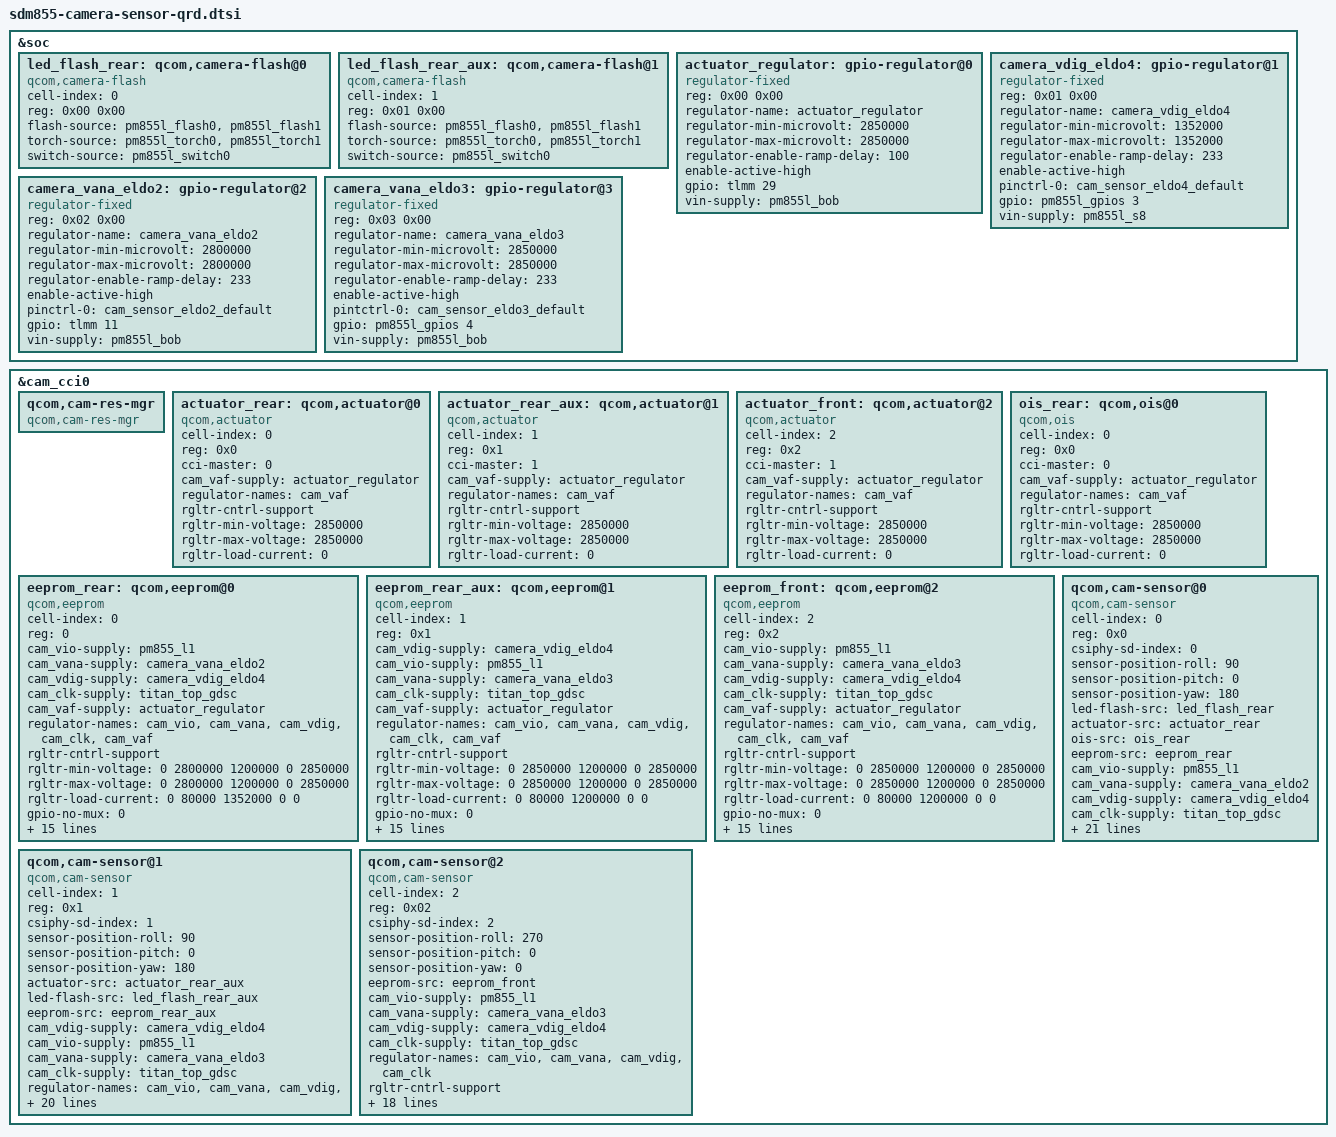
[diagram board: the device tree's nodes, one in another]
/*
 * Copyright (c) 2018, The Linux Foundation. All rights reserved.
 *
 * This program is free software; you can redistribute it and/or modify
 * it under the terms of the GNU General Public License version 2 and
 * only version 2 as published by the Free Software Foundation.
 *
 * This program is distributed in the hope that it will be useful,
 * but WITHOUT ANY WARRANTY; without even the implied warranty of
 * MERCHANTABILITY or FITNESS FOR A PARTICULAR PURPOSE.  See the
 * GNU General Public License for more details.
 */

&soc {
	led_flash_rear: qcom,camera-flash@0 {
		cell-index = <0>;
		reg = <0x00 0x00>;
		compatible = "qcom,camera-flash";
		flash-source = <&pm855l_flash0 &pm855l_flash1>;
		torch-source = <&pm855l_torch0 &pm855l_torch1>;
		switch-source = <&pm855l_switch0>;
		status = "ok";
	};

	led_flash_rear_aux: qcom,camera-flash@1 {
		cell-index = <1>;
		reg = <0x01 0x00>;
		compatible = "qcom,camera-flash";
		flash-source = <&pm855l_flash0 &pm855l_flash1>;
		torch-source = <&pm855l_torch0 &pm855l_torch1>;
		switch-source = <&pm855l_switch0>;
		status = "ok";
	};

	actuator_regulator: gpio-regulator@0 {
		compatible = "regulator-fixed";
		reg = <0x00 0x00>;
		regulator-name = "actuator_regulator";
		regulator-min-microvolt = <2850000>;
		regulator-max-microvolt = <2850000>;
		regulator-enable-ramp-delay = <100>;
		enable-active-high;
		gpio = <&tlmm 29 0>;
		vin-supply = <&pm855l_bob>;
	};

	camera_vdig_eldo4: gpio-regulator@1 {
		compatible = "regulator-fixed";
		reg = <0x01 0x00>;
		regulator-name = "camera_vdig_eldo4";
		regulator-min-microvolt = <1352000>;
		regulator-max-microvolt = <1352000>;
		regulator-enable-ramp-delay = <233>;
		enable-active-high;
		pinctrl-names = "default";
		pinctrl-0 = <&cam_sensor_eldo4_default>;
		gpio = <&pm855l_gpios 3 0>;
		vin-supply = <&pm855l_s8>;
	};

	camera_vana_eldo2: gpio-regulator@2 {
		compatible = "regulator-fixed";
		reg = <0x02 0x00>;
		regulator-name = "camera_vana_eldo2";
		regulator-min-microvolt = <2800000>;
		regulator-max-microvolt = <2800000>;
		regulator-enable-ramp-delay = <233>;
		enable-active-high;
		pinctrl-names = "default";
		pinctrl-0 = <&cam_sensor_eldo2_default>;
		gpio = <&tlmm 11 0>;
		vin-supply = <&pm855l_bob>;
	};

	camera_vana_eldo3: gpio-regulator@3 {
		compatible = "regulator-fixed";
		reg = <0x03 0x00>;
		regulator-name = "camera_vana_eldo3";
		regulator-min-microvolt = <2850000>;
		regulator-max-microvolt = <2850000>;
		regulator-enable-ramp-delay = <233>;
		enable-active-high;
		pinctrl-names = "default";
		pintctrl-0 = <&cam_sensor_eldo3_default>;
		gpio = <&pm855l_gpios 4 0>;
		vin-supply = <&pm855l_bob>;
	};

};

&cam_cci0 {
	qcom,cam-res-mgr {
		compatible = "qcom,cam-res-mgr";
		status = "ok";
	};

	actuator_rear: qcom,actuator@0 {
		cell-index = <0>;
		reg = <0x0>;
		compatible = "qcom,actuator";
		cci-master = <0>;
		cam_vaf-supply = <&actuator_regulator>;
		regulator-names = "cam_vaf";
		rgltr-cntrl-support;
		rgltr-min-voltage = <2850000>;
		rgltr-max-voltage = <2850000>;
		rgltr-load-current = <0>;
	};

	actuator_rear_aux: qcom,actuator@1 {
		cell-index = <1>;
		reg = <0x1>;
		compatible = "qcom,actuator";
		cci-master = <1>;
		cam_vaf-supply = <&actuator_regulator>;
		regulator-names = "cam_vaf";
		rgltr-cntrl-support;
		rgltr-min-voltage = <2850000>;
		rgltr-max-voltage = <2850000>;
		rgltr-load-current = <0>;
	};

	actuator_front: qcom,actuator@2 {
		cell-index = <2>;
		reg = <0x2>;
		compatible = "qcom,actuator";
		cci-master = <1>;
		cam_vaf-supply = <&actuator_regulator>;
		regulator-names = "cam_vaf";
		rgltr-cntrl-support;
		rgltr-min-voltage = <2850000>;
		rgltr-max-voltage = <2850000>;
		rgltr-load-current = <0>;
	};

	ois_rear: qcom,ois@0 {
		cell-index = <0>;
		reg = <0x0>;
		compatible = "qcom,ois";
		cci-master = <0>;
		cam_vaf-supply = <&actuator_regulator>;
		regulator-names = "cam_vaf";
		rgltr-cntrl-support;
		rgltr-min-voltage = <2850000>;
		rgltr-max-voltage = <2850000>;
		rgltr-load-current = <0>;
		status = "ok";
	};

	eeprom_rear: qcom,eeprom@0 {
		cell-index = <0>;
		reg = <0>;
		compatible = "qcom,eeprom";
		cam_vio-supply = <&pm855_l1>;
		cam_vana-supply = <&camera_vana_eldo2>;
		cam_vdig-supply = <&camera_vdig_eldo4>;
		cam_clk-supply = <&titan_top_gdsc>;
		cam_vaf-supply = <&actuator_regulator>;
		regulator-names = "cam_vio", "cam_vana", "cam_vdig",
			"cam_clk", "cam_vaf";
		rgltr-cntrl-support;
		rgltr-min-voltage = <0 2800000 1200000 0 2850000>;
		rgltr-max-voltage = <0 2800000 1200000 0 2850000>;
		rgltr-load-current = <0 80000 1352000 0 0>;
		gpio-no-mux = <0>;
		pinctrl-names = "cam_default", "cam_suspend";
		pinctrl-0 = <&cam_sensor_mclk0_active
				&cam_sensor_active_rear>;
		pinctrl-1 = <&cam_sensor_mclk0_suspend
				&cam_sensor_suspend_rear>;
		gpios = <&tlmm 13 0>,
			<&tlmm 28 0>;
		gpio-reset = <1>;
		gpio-req-tbl-num = <0 1>;
		gpio-req-tbl-flags = <1 0>;
		gpio-req-tbl-label = "CAMIF_MCLK0",
					"CAM_RESET0";
		sensor-position = <0>;
		sensor-mode = <0>;
		cci-master = <0>;
		status = "ok";
		clocks = <&clock_camcc CAM_CC_MCLK0_CLK>;
		clock-names = "cam_clk";
		clock-cntl-level = "turbo";
		clock-rates = <24000000>;
	};

	eeprom_rear_aux: qcom,eeprom@1 {
		cell-index = <1>;
		reg = <0x1>;
		compatible = "qcom,eeprom";
		cam_vdig-supply = <&camera_vdig_eldo4>;
		cam_vio-supply = <&pm855_l1>;
		cam_vana-supply = <&camera_vana_eldo3>;
		cam_clk-supply = <&titan_top_gdsc>;
		cam_vaf-supply = <&actuator_regulator>;
		regulator-names = "cam_vio", "cam_vana", "cam_vdig",
			"cam_clk", "cam_vaf";
		rgltr-cntrl-support;
		rgltr-min-voltage = <0 2850000 1200000 0 2850000>;
		rgltr-max-voltage = <0 2850000 1200000 0 2850000>;
		rgltr-load-current = <0 80000 1200000 0 0>;
		gpio-no-mux = <0>;
		pinctrl-names = "cam_default", "cam_suspend";
		pinctrl-0 = <&cam_sensor_mclk1_active
				&cam_sensor_active_rear_aux>;
		pinctrl-1 = <&cam_sensor_mclk1_suspend
				&cam_sensor_suspend_rear_aux>;
		gpios = <&tlmm 14 0>,
			<&tlmm 30 0>;
		gpio-reset = <1>;
		gpio-req-tbl-num = <0 1>;
		gpio-req-tbl-flags = <1 0>;
		gpio-req-tbl-label = "CAMIF_MCLK1",
					"CAM_RESET1";
		sensor-position = <0>;
		sensor-mode = <0>;
		cci-master = <1>;
		status = "ok";
		clocks = <&clock_camcc CAM_CC_MCLK2_CLK>;
		clock-names = "cam_clk";
		clock-cntl-level = "turbo";
		clock-rates = <24000000>;
	};

	eeprom_front: qcom,eeprom@2 {
		cell-index = <2>;
		reg = <0x2>;
		compatible = "qcom,eeprom";
		cam_vio-supply = <&pm855_l1>;
		cam_vana-supply = <&camera_vana_eldo3>;
		cam_vdig-supply = <&camera_vdig_eldo4>;
		cam_clk-supply = <&titan_top_gdsc>;
		cam_vaf-supply = <&actuator_regulator>;
		regulator-names = "cam_vio", "cam_vana", "cam_vdig",
			"cam_clk", "cam_vaf";
		rgltr-cntrl-support;
		rgltr-min-voltage = <0 2850000 1200000 0 2850000>;
		rgltr-max-voltage = <0 2850000 1200000 0 2850000>;
		rgltr-load-current = <0 80000 1200000 0 0>;
		gpio-no-mux = <0>;
		pinctrl-names = "cam_default", "cam_suspend";
		pinctrl-0 = <&cam_sensor_mclk2_active
				 &cam_sensor_active_front>;
		pinctrl-1 = <&cam_sensor_mclk2_suspend
				 &cam_sensor_suspend_front>;
		gpios = <&tlmm 15 0>,
			<&tlmm 12 0>;
		gpio-reset = <1>;
		gpio-req-tbl-num = <0 1>;
		gpio-req-tbl-flags = <1 0>;
		gpio-req-tbl-label = "CAMIF_MCLK2",
					"CAM_RESET2";
		sensor-position = <1>;
		sensor-mode = <0>;
		cci-master = <1>;
		status = "ok";
		clocks = <&clock_camcc CAM_CC_MCLK2_CLK>;
		clock-names = "cam_clk";
		clock-cntl-level = "turbo";
		clock-rates = <24000000>;
	};

	qcom,cam-sensor@0 {
		cell-index = <0>;
		compatible = "qcom,cam-sensor";
		reg = <0x0>;
		csiphy-sd-index = <0>;
		sensor-position-roll = <90>;
		sensor-position-pitch = <0>;
		sensor-position-yaw = <180>;
		led-flash-src = <&led_flash_rear>;
		actuator-src = <&actuator_rear>;
		ois-src = <&ois_rear>;
		eeprom-src = <&eeprom_rear>;
		cam_vio-supply = <&pm855_l1>;
		cam_vana-supply = <&camera_vana_eldo2>;
		cam_vdig-supply = <&camera_vdig_eldo4>;
		cam_clk-supply = <&titan_top_gdsc>;
		regulator-names = "cam_vio", "cam_vana", "cam_vdig",
			"cam_clk";
		rgltr-cntrl-support;
		rgltr-min-voltage = <0 2800000 1200000 0>;
		rgltr-max-voltage = <0 2800000 1200000 0>;
		rgltr-load-current = <0 80000 1200000 0>;
		gpio-no-mux = <0>;
		pinctrl-names = "cam_default", "cam_suspend";
		pinctrl-0 = <&cam_sensor_mclk0_active
				&cam_sensor_active_rear>;
		pinctrl-1 = <&cam_sensor_mclk0_suspend
				&cam_sensor_suspend_rear>;
		gpios = <&tlmm 13 0>,
			<&tlmm 28 0>;
		gpio-reset = <1>;
		gpio-req-tbl-num = <0 1>;
		gpio-req-tbl-flags = <1 0>;
		gpio-req-tbl-label = "CAMIF_MCLK0",
					"CAM_RESET0";
		sensor-mode = <0>;
		cci-master = <0>;
		status = "ok";
		clocks = <&clock_camcc CAM_CC_MCLK0_CLK>;
		clock-names = "cam_clk";
		clock-cntl-level = "turbo";
		clock-rates = <24000000>;
	};

	qcom,cam-sensor@1 {
		cell-index = <1>;
		compatible = "qcom,cam-sensor";
		reg = <0x1>;
		csiphy-sd-index = <1>;
		sensor-position-roll = <90>;
		sensor-position-pitch = <0>;
		sensor-position-yaw = <180>;
		actuator-src = <&actuator_rear_aux>;
		led-flash-src = <&led_flash_rear_aux>;
		eeprom-src = <&eeprom_rear_aux>;
		cam_vdig-supply = <&camera_vdig_eldo4>;
		cam_vio-supply = <&pm855_l1>;
		cam_vana-supply = <&camera_vana_eldo3>;
		cam_clk-supply = <&titan_top_gdsc>;
		regulator-names = "cam_vio", "cam_vana", "cam_vdig",
			"cam_clk";
		rgltr-cntrl-support;
		rgltr-min-voltage = <0 2850000 1200000 0>;
		rgltr-max-voltage = <0 2850000 1200000 0>;
		rgltr-load-current = <0 80000 1200000 0>;
		gpio-no-mux = <0>;
		pinctrl-names = "cam_default", "cam_suspend";
		pinctrl-0 = <&cam_sensor_mclk1_active
				&cam_sensor_active_rear_aux>;
		pinctrl-1 = <&cam_sensor_mclk1_suspend
				&cam_sensor_suspend_rear_aux>;
		gpios = <&tlmm 14 0>,
			<&tlmm 30 0>;
		gpio-reset = <1>;
		gpio-req-tbl-num = <0 1>;
		gpio-req-tbl-flags = <1 0>;
		gpio-req-tbl-label = "CAMIF_MCLK1",
					"CAM_RESET1";
		sensor-mode = <0>;
		cci-master = <1>;
		status = "ok";
		clocks = <&clock_camcc CAM_CC_MCLK1_CLK>;
		clock-names = "cam_clk";
		clock-cntl-level = "turbo";
		clock-rates = <24000000>;
	};

	qcom,cam-sensor@2 {
		cell-index = <2>;
		compatible = "qcom,cam-sensor";
		reg = <0x02>;
		csiphy-sd-index = <2>;
		sensor-position-roll = <270>;
		sensor-position-pitch = <0>;
		sensor-position-yaw = <0>;
		eeprom-src = <&eeprom_front>;
		cam_vio-supply = <&pm855_l1>;
		cam_vana-supply = <&camera_vana_eldo3>;
		cam_vdig-supply = <&camera_vdig_eldo4>;
		cam_clk-supply = <&titan_top_gdsc>;
		regulator-names = "cam_vio", "cam_vana", "cam_vdig",
			"cam_clk";
		rgltr-cntrl-support;
		rgltr-min-voltage = <0 2850000 1200000 0>;
		rgltr-max-voltage = <0 2850000 1200000 0>;
		rgltr-load-current = <0 80000 1200000 0>;
		gpio-no-mux = <0>;
		pinctrl-names = "cam_default", "cam_suspend";
		pinctrl-0 = <&cam_sensor_mclk2_active
				 &cam_sensor_active_front>;
		pinctrl-1 = <&cam_sensor_mclk2_suspend
				 &cam_sensor_suspend_front>;
		gpios = <&tlmm 15 0>,
			<&tlmm 12 0>;
		gpio-reset = <1>;
		gpio-req-tbl-num = <0 1>;
		gpio-req-tbl-flags = <1 0>;
		gpio-req-tbl-label = "CAMIF_MCLK2",
					"CAM_RESET2";
		sensor-mode = <0>;
		cci-master = <1>;
		status = "ok";
		clocks = <&clock_camcc CAM_CC_MCLK2_CLK>;
		clock-names = "cam_clk";
		clock-cntl-level = "turbo";
		clock-rates = <24000000>;
	};
};
